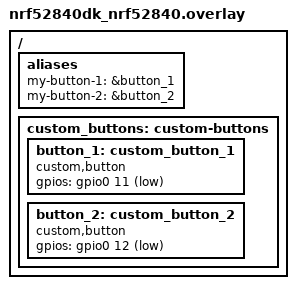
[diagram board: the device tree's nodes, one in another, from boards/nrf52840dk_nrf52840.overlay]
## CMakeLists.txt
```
cmake_minimum_required(VERSION 3.20.0)

# Must be before find_package(Zephyr ...)
set(ZEPHYR_EXTRA_MODULES "${CMAKE_CURRENT_SOURCE_DIR}/modules/button")

find_package(Zephyr REQUIRED HINTS $ENV{ZEPHYR_BASE})
project(button_driver_example)

target_sources(app PRIVATE src/main.c)
```

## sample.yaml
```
sample:
  name: Button Driver Example
  description: >
    Demonstrates creating a custom GPIO button driver in Zephyr,
    including devicetree integration and usage in an application.
  boards:
    - nrf52840dk_nrf52840
  tags: drivers gpio
```

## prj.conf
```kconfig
CONFIG_CUSTOM_BUTTON=y
CONFIG_LOG=y
CONFIG_LOG_DEFAULT_LEVEL=3
CONFIG_GPIO=y
```

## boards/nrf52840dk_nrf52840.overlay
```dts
/ {
    aliases {
        my-button-1 = &button_1;
        my-button-2 = &button_2;
    };

    custom_buttons: custom-buttons {
        button_1: custom_button_1 {
            compatible = "custom,button";
            gpios = <&gpio0 11 (GPIO_PULL_UP | GPIO_ACTIVE_LOW)>;
            status = "okay";
        };

        button_2: custom_button_2 {
            compatible = "custom,button";
            gpios = <&gpio0 12 (GPIO_PULL_UP | GPIO_ACTIVE_LOW)>;
            status = "okay";
        };
    };
};
```

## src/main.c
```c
#include <stdio.h>
#include <zephyr/kernel.h>
#include "button.h"

// Settings
static const int32_t sleep_time_ms = 50;
const struct device *btn_1 = DEVICE_DT_GET(DT_ALIAS(my_button_1));
const struct device *btn_2 = DEVICE_DT_GET(DT_ALIAS(my_button_2));


int main(void)
{
        int ret;
        uint8_t state_1;
        uint8_t state_2;

        // Make sure that the button was initalized
        if (!(device_is_ready(btn_1) && device_is_ready(btn_2))){
                printk("Error: buttons are not ready\r\n");
                return 0;
        }

        // Get the API from one of the buttons
        const struct button_api *btn_api = (const struct button_api *)btn_1->api;

        // Do forever
        while (1) {
                //poll the button 1 state
                ret = btn_api->get(btn_1, &state_1);
                if (ret < 0) {
                        printk("Error (%d): failed to read button 1 pin\r\n", ret);
                        continue;
                }
                  ret = btn_api->get(btn_2, &state_2);
                if (ret < 0) {
                        printk("Error (%d): failed to read button 2 pin\r\n", ret);
                        continue;
                }

                // Print button states
                printk("%u %u\r\n", state_1, state_2);

                // Sleep
                k_msleep(sleep_time_ms);
        }
        return 0;
}
```
